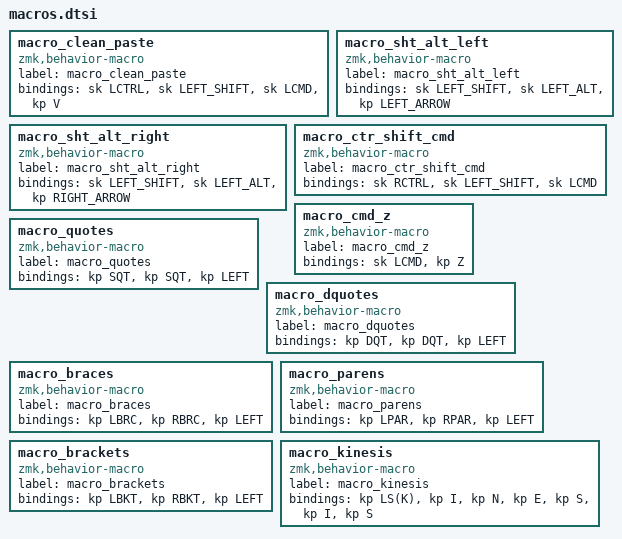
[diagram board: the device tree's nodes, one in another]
macro_clean_paste: macro_clean_paste{
compatible = "zmk,behavior-macro";
label = "macro_clean_paste";
#binding-cells = <0>;
bindings = <&sk LCTRL>, <&sk LEFT_SHIFT>, <&sk LCMD>, <&kp V>;
};
macro_sht_alt_left: macro_sht_alt_left{
compatible = "zmk,behavior-macro";
label = "macro_sht_alt_left";
#binding-cells = <0>;
bindings = <&sk LEFT_SHIFT>, <&sk LEFT_ALT>, <&kp LEFT_ARROW>;
};
macro_sht_alt_right: macro_sht_alt_right{
compatible = "zmk,behavior-macro";
label = "macro_sht_alt_right";
#binding-cells = <0>;
bindings = <&sk LEFT_SHIFT>, <&sk LEFT_ALT>, <&kp RIGHT_ARROW>;
};
macro_ctr_shift_cmd: macro_ctr_shift_cmd{
compatible = "zmk,behavior-macro";
label = "macro_ctr_shift_cmd";
#binding-cells = <0>;
bindings = <&sk RCTRL>, <&sk LEFT_SHIFT>, <&sk LCMD>;
};
macro_cmd_z: macro_cmd_z{
compatible = "zmk,behavior-macro";
label = "macro_cmd_z";
#binding-cells = <0>;
bindings = <&sk LCMD>, <&kp Z>;
};
macro_quotes: macro_quotes{
compatible = "zmk,behavior-macro";
label = "macro_quotes";
#binding-cells = <0>;
bindings = <&kp SQT>, <&kp SQT>, <&kp LEFT>;
};
macro_dquotes: macro_dquotes{
compatible = "zmk,behavior-macro";
label = "macro_dquotes";
#binding-cells = <0>;
bindings = <&kp DQT>, <&kp DQT>, <&kp LEFT>;
};
macro_braces: macro_braces{
compatible = "zmk,behavior-macro";
label = "macro_braces";
#binding-cells = <0>;
bindings = <&kp LBRC>, <&kp RBRC>, <&kp LEFT>;
};
macro_parens: macro_parens{
compatible = "zmk,behavior-macro";
label = "macro_parens";
#binding-cells = <0>;
bindings = <&kp LPAR>, <&kp RPAR>, <&kp LEFT>;
};
macro_brackets: macro_brackets{
compatible = "zmk,behavior-macro";
label = "macro_brackets";
#binding-cells = <0>;
bindings = <&kp LBKT>, <&kp RBKT>, <&kp LEFT>;
};
macro_kinesis: macro_kinesis{
compatible = "zmk,behavior-macro";
label = "macro_kinesis";
#binding-cells = <0>;
bindings = <&kp LS(K)>, <&kp I>, <&kp N>, <&kp E>, <&kp S>, <&kp I>, <&kp S>;
};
